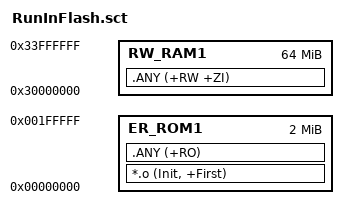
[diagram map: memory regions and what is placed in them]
; *************************************************************
; *** Scatter-Loading Description File generated by uVision ***
; ***			Run program in flash	          		    ***
; *************************************************************

LR_ROM1 0x00000000   {    ; load region size_region
  ER_ROM1 0x00000000 0x00200000  {  ;2MB load address = execution address
   *.o (Init, +First)
;   *(InRoot$$Sections)
   .ANY (+RO)
  }
  RW_RAM1 0x30000000 0x04000000  {  ; RW data
   .ANY (+RW +ZI)
  }
}

